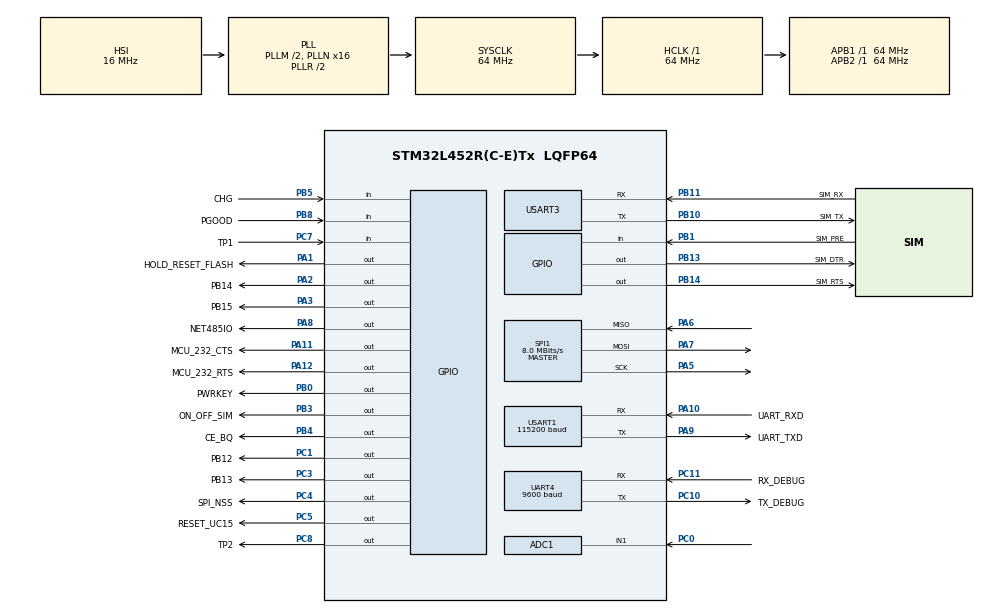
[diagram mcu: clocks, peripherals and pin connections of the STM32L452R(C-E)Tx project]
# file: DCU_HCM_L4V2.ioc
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ADC1.Channel-0\#ChannelRegularConversion=ADC_CHANNEL_1
ADC1.Channel-1\#ChannelRegularConversion=ADC_CHANNEL_VREFINT
ADC1.NbrOfConversion=2
ADC1.NbrOfConversionFlag=1
ADC1.OffsetNumber-0\#ChannelRegularConversion=ADC_OFFSET_NONE
ADC1.OffsetNumber-1\#ChannelRegularConversion=ADC_OFFSET_NONE
ADC1.Rank-0\#ChannelRegularConversion=1
ADC1.Rank-1\#ChannelRegularConversion=2
ADC1.SamplingTime-0\#ChannelRegularConversion=ADC_SAMPLETIME_640CYCLES_5
ADC1.SamplingTime-1\#ChannelRegularConversion=ADC_SAMPLETIME_640CYCLES_5
ADC1.master=1
IWDG.Prescaler=IWDG_PRESCALER_32
Mcu.Family=STM32L4
Mcu.Name=STM32L452R(C-E)Tx
Mcu.Package=LQFP64
NVIC.PriorityGroup=NVIC_PRIORITYGROUP_4
NVIC.TIM1_UP_TIM16_IRQn=true\:15\:0\:false\:false\:true\:false\:true
NVIC.TimeBase=TIM1_UP_TIM16_IRQn
NVIC.TimeBaseIP=TIM1
NVIC.UART4_IRQn=true\:0\:0\:false\:false\:true\:true\:true
NVIC.USART1_IRQn=true\:0\:0\:false\:false\:true\:true\:true
NVIC.USART3_IRQn=true\:0\:0\:false\:false\:true\:true\:true
PA1.GPIO_Label=HOLD_RESET_FLASH
PA1.GPIO_PuPd=GPIO_PULLUP
PA1.GPIO_Speed=GPIO_SPEED_FREQ_VERY_HIGH
PA1.PinState=GPIO_PIN_SET
PA1.Signal=GPIO_Output
PA10.GPIO_Label=UART_RXD
PA10.Mode=Asynchronous
PA10.Signal=USART1_RX
PA11.GPIO_Label=MCU_232_CTS
PA11.GPIO_PuPd=GPIO_PULLUP
PA11.PinState=GPIO_PIN_RESET
PA11.Signal=GPIO_Output
PA12.GPIO_Label=MCU_232_RTS
PA12.GPIO_PuPd=GPIO_PULLUP
PA12.GPIO_Speed=GPIO_SPEED_FREQ_MEDIUM
PA12.Signal=GPIO_Output
PA13\ (JTMS/SWDIO).Mode=Serial_Wire
PA13\ (JTMS/SWDIO).Signal=SYS_JTMS-SWDIO
PA14\ (JTCK/SWCLK).Mode=Serial_Wire
PA14\ (JTCK/SWCLK).Signal=SYS_JTCK-SWCLK
PA2.GPIO_Label=PB14
PA2.PinState=GPIO_PIN_SET
PA2.Signal=GPIO_Output
PA3.GPIO_Label=PB15
PA3.PinState=GPIO_PIN_SET
PA3.Signal=GPIO_Output
PA5.Mode=Full_Duplex_Master
PA5.Signal=SPI1_SCK
PA6.Mode=Full_Duplex_Master
PA6.Signal=SPI1_MISO
PA7.Mode=Full_Duplex_Master
PA7.Signal=SPI1_MOSI
PA8.GPIO_Label=NET485IO
PA8.GPIO_PuPd=GPIO_PULLUP
PA8.GPIO_Speed=GPIO_SPEED_FREQ_HIGH
PA8.PinState=GPIO_PIN_RESET
PA8.Signal=GPIO_Output
PA9.GPIO_Label=UART_TXD
PA9.Mode=Asynchronous
PA9.Signal=USART1_TX
PB0.GPIO_Label=PWRKEY
PB0.GPIO_PuPd=GPIO_PULLUP
PB0.Signal=GPIO_Output
PB1.GPIO_Label=SIM_PRE
PB1.GPIO_PuPd=GPIO_PULLUP
PB1.Signal=GPIO_Input
PB10.GPIO_Label=SIM_TX
PB10.Mode=Asynchronous
PB10.Signal=USART3_TX
PB11.GPIO_Label=SIM_RX
PB11.Mode=Asynchronous
PB11.Signal=USART3_RX
PB13.GPIO_Label=SIM_DTR
PB13.GPIO_Speed=GPIO_SPEED_FREQ_HIGH
PB13.PinState=GPIO_PIN_SET
PB13.Signal=GPIO_Output
PB14.GPIO_Label=SIM_RTS
PB14.Signal=GPIO_Output
PB3\ (JTDO/TRACESWO).GPIO_Label=ON_OFF_SIM
PB3\ (JTDO/TRACESWO).GPIO_PuPd=GPIO_PULLUP
PB3\ (JTDO/TRACESWO).Signal=GPIO_Output
PB4\ (NJTRST).GPIO_Label=CE_BQ
PB4\ (NJTRST).GPIO_PuPd=GPIO_PULLUP
PB4\ (NJTRST).Signal=GPIO_Output
PB5.GPIO_Label=CHG
PB5.GPIO_PuPd=GPIO_PULLUP
PB5.Signal=GPIO_Input
PB8.GPIO_Label=PGOOD
PB8.GPIO_PuPd=GPIO_PULLUP
PB8.Signal=GPIO_Input
PC0.Signal=ADCx_IN1
PC1.GPIO_Label=PB12
PC1.PinState=GPIO_PIN_SET
PC1.Signal=GPIO_Output
PC10.GPIO_Label=TX_DEBUG
PC10.Mode=Asynchronous
PC10.Signal=UART4_TX
PC11.GPIO_Label=RX_DEBUG
PC11.Mode=Asynchronous
PC11.Signal=UART4_RX
PC14-OSC32_IN\ (PC14).Mode=LSE-External-Oscillator
PC14-OSC32_IN\ (PC14).Signal=RCC_OSC32_IN
PC15-OSC32_OUT\ (PC15).Mode=LSE-External-Oscillator
PC15-OSC32_OUT\ (PC15).Signal=RCC_OSC32_OUT
PC3.GPIO_Label=PB13
PC3.PinState=GPIO_PIN_SET
PC3.Signal=GPIO_Output
PC4.GPIO_Label=SPI_NSS
PC4.GPIO_PuPd=GPIO_PULLUP
PC4.PinState=GPIO_PIN_SET
PC4.Signal=GPIO_Output
PC5.GPIO_Label=RESET_UC15
PC5.Signal=GPIO_Output
PC7.GPIO_Label=TP1
PC7.GPIO_PuPd=GPIO_PULLDOWN
PC7.Signal=GPIO_Input
PC8.GPIO_Label=TP2
PC8.GPIO_Speed=GPIO_SPEED_FREQ_MEDIUM
PC8.PinState=GPIO_PIN_SET
PC8.Signal=GPIO_Output
ProjectManager.HeapSize=0x200
ProjectManager.StackSize=0x400
ProjectManager.TargetToolchain=STM32CubeIDE
RCC.ADCFreq_Value=64000000
RCC.AHBFreq_Value=64000000
RCC.APB1Freq_Value=64000000
RCC.APB1TimFreq_Value=64000000
RCC.APB2Freq_Value=64000000
RCC.APB2TimFreq_Value=64000000
RCC.CortexFreq_Value=64000000
RCC.HCLKFreq_Value=64000000
RCC.HSE_VALUE=8000000
RCC.HSI48_VALUE=48000000
RCC.HSI_VALUE=16000000
RCC.MSI_VALUE=4000000
RCC.PLLM=2
RCC.PLLN=16
RCC.PLLSAI1N=16
RCC.PLLSourceVirtual=RCC_PLLSOURCE_HSI
RCC.RTCClockSelection=RCC_RTCCLKSOURCE_LSE
RCC.SYSCLKFreq_VALUE=64000000
RCC.SYSCLKSource=RCC_SYSCLKSOURCE_PLLCLK
RCC.UART4CLockSelection=RCC_UART4CLKSOURCE_HSI
RCC.USBFreq_Value=64000000
RCC.VCOOutputFreq_Value=128000000
SH.ADCx_IN1.0=ADC1_IN1,IN1-Single-Ended
SPI1.BaudRatePrescaler=SPI_BAUDRATEPRESCALER_8
SPI1.CalculateBaudRate=8.0 MBits/s
SPI1.DataSize=SPI_DATASIZE_8BIT
SPI1.Direction=SPI_DIRECTION_2LINES
SPI1.Mode=SPI_MODE_MASTER
SPI1.VirtualType=VM_MASTER
UART4.BaudRate=9600
UART4.Parity=PARITY_EVEN
USART1.BaudRate=115200
USART1.VirtualMode-Asynchronous=VM_ASYNC
USART3.VirtualMode-Asynchronous=VM_ASYNC
VP_ADC1_Vref_Input.Mode=IN-Vrefint
VP_IWDG_VS_IWDG.Mode=IWDG_Activate
VP_RTC_VS_RTC_Activate.Mode=RTC_Enabled
VP_SYS_VS_tim1.Mode=TIM1
board=custom

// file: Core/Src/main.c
/* USER CODE BEGIN Header */
/**
  ******************************************************************************
  * @file           : main.c
  * @brief          : Main program body
  ******************************************************************************
  * @attention
  *
  * <h2><center>&copy; Copyright (c) 2021 STMicroelectronics.
  * All rights reserved.</center></h2>
  *
  * This software component is licensed by ST under BSD 3-Clause license,
  * the "License"; You may not use this file except in compliance with the
  * License. You may obtain a copy of the License at:
  *                        opensource.org/licenses/BSD-3-Clause
  *
  ******************************************************************************
  */
/* USER CODE END Header */
#include "main.h"
#include "adc.h"
#include "iwdg.h"
#include "rtc.h"
#include "spi.h"
#include "usart.h"
#include "gpio.h"

/* USER CODE BEGIN Includes */
#include "main_app.h"
/* USER CODE END Includes */

void SystemClock_Config(void);

int main(void)
{

  /* MCU Configuration--------------------------------------------------------*/

  /* Reset of all peripherals, Initializes the Flash interface and the Systick. */
  HAL_Init();

  /* USER CODE BEGIN Init */
// Init SystemClock with MSI or HSI to ensure that the system clock will never error
// Check RTC data is storage in flash if have valid data so we should use LSE otherwise use LSI
  /* USER CODE END Init */

  /* Configure the system clock */
  SystemClock_Config();

  /* USER CODE BEGIN SysInit */
/* The IWDG should be initialization before other peripherals */
//  MX_IWDG_Init();
/* Initialization step by step each of peripherals, if they are error so switches to default initialization
 * switch (step)
 * {
 * 		step_err = read_flash_step_init_error() + 1;
 * 		if (step = step_err)
 * 			step += 1; // jump to next step
 *
 * 		case 1:
 * 		MX_GPIO_Init(); // control LED to know the system will be work fine
 * 		// store this step in flash
 * 		break;
 * 		case 2:
 * 		MX_RTC_Init_LSE();
 * 		// store this step in flash
 * 		break;
 * 		case 3:
 * 		MX_RTC_Init_LSI(); // switches to LSI if LSE is error
 * 		// store this step in flash
 * 		case 4:
 * 		MX_ADC1_Init();
 * 		// store this step in flash
 *		break;
 *		default:
 *		break;
 * };
 *
 * */

  /* USER CODE END SysInit */

  /* Initialize all configured peripherals */
  MX_GPIO_Init();
  MX_ADC1_Init();
  MX_RTC_Init();
  MX_SPI1_Init();
  MX_UART4_Init();
  MX_USART1_UART_Init();
  MX_USART3_UART_Init();
//  MX_IWDG_Init();

  /* Infinite loop */
  /* USER CODE BEGIN WHILE */
  while (1)
  {
	  MainTask();
    /* USER CODE END WHILE */

  }
}

void SystemClock_Config(void)
{
  RCC_OscInitTypeDef RCC_OscInitStruct = {0};
  RCC_ClkInitTypeDef RCC_ClkInitStruct = {0};

  /** Configure the main internal regulator output voltage
  */
  if (HAL_PWREx_ControlVoltageScaling(PWR_REGULATOR_VOLTAGE_SCALE1) != HAL_OK)
  {
    Error_Handler();
  }
  /** Configure LSE Drive Capability
  */
  HAL_PWR_EnableBkUpAccess();
  __HAL_RCC_LSEDRIVE_CONFIG(RCC_LSEDRIVE_LOW);
  /** Initializes the RCC Oscillators according to the specified parameters
  * in the RCC_OscInitTypeDef structure.
  */
  RCC_OscInitStruct.OscillatorType = RCC_OSCILLATORTYPE_HSI|RCC_OSCILLATORTYPE_LSI
                              |RCC_OSCILLATORTYPE_LSE;
  RCC_OscInitStruct.LSEState = RCC_LSE_ON;
  RCC_OscInitStruct.HSIState = RCC_HSI_ON;
  RCC_OscInitStruct.HSICalibrationValue = RCC_HSICALIBRATION_DEFAULT;
  RCC_OscInitStruct.LSIState = RCC_LSI_ON;
  RCC_OscInitStruct.PLL.PLLState = RCC_PLL_ON;
  RCC_OscInitStruct.PLL.PLLSource = RCC_PLLSOURCE_HSI;
  RCC_OscInitStruct.PLL.PLLM = 2;
  RCC_OscInitStruct.PLL.PLLN = 16;
  RCC_OscInitStruct.PLL.PLLP = RCC_PLLP_DIV7;
  RCC_OscInitStruct.PLL.PLLQ = RCC_PLLQ_DIV2;
  RCC_OscInitStruct.PLL.PLLR = RCC_PLLR_DIV2;
  if (HAL_RCC_OscConfig(&RCC_OscInitStruct) != HAL_OK)
  {
    Error_Handler();
  }
  /** Initializes the CPU, AHB and APB buses clocks
  */
  RCC_ClkInitStruct.ClockType = RCC_CLOCKTYPE_HCLK|RCC_CLOCKTYPE_SYSCLK
                              |RCC_CLOCKTYPE_PCLK1|RCC_CLOCKTYPE_PCLK2;
  RCC_ClkInitStruct.SYSCLKSource = RCC_SYSCLKSOURCE_PLLCLK;
  RCC_ClkInitStruct.AHBCLKDivider = RCC_SYSCLK_DIV1;
  RCC_ClkInitStruct.APB1CLKDivider = RCC_HCLK_DIV1;
  RCC_ClkInitStruct.APB2CLKDivider = RCC_HCLK_DIV1;

  if (HAL_RCC_ClockConfig(&RCC_ClkInitStruct, FLASH_LATENCY_3) != HAL_OK)
  {
    Error_Handler();
  }
}

void HAL_TIM_PeriodElapsedCallback(TIM_HandleTypeDef *htim)
{
  if (htim->Instance == TIM1) {
    HAL_IncTick();
  }
}

void Error_Handler(void)
{
  __disable_irq();
  while (1)
  {
  }
}

/************************ (C) COPYRIGHT STMicroelectronics *****END OF FILE****/
